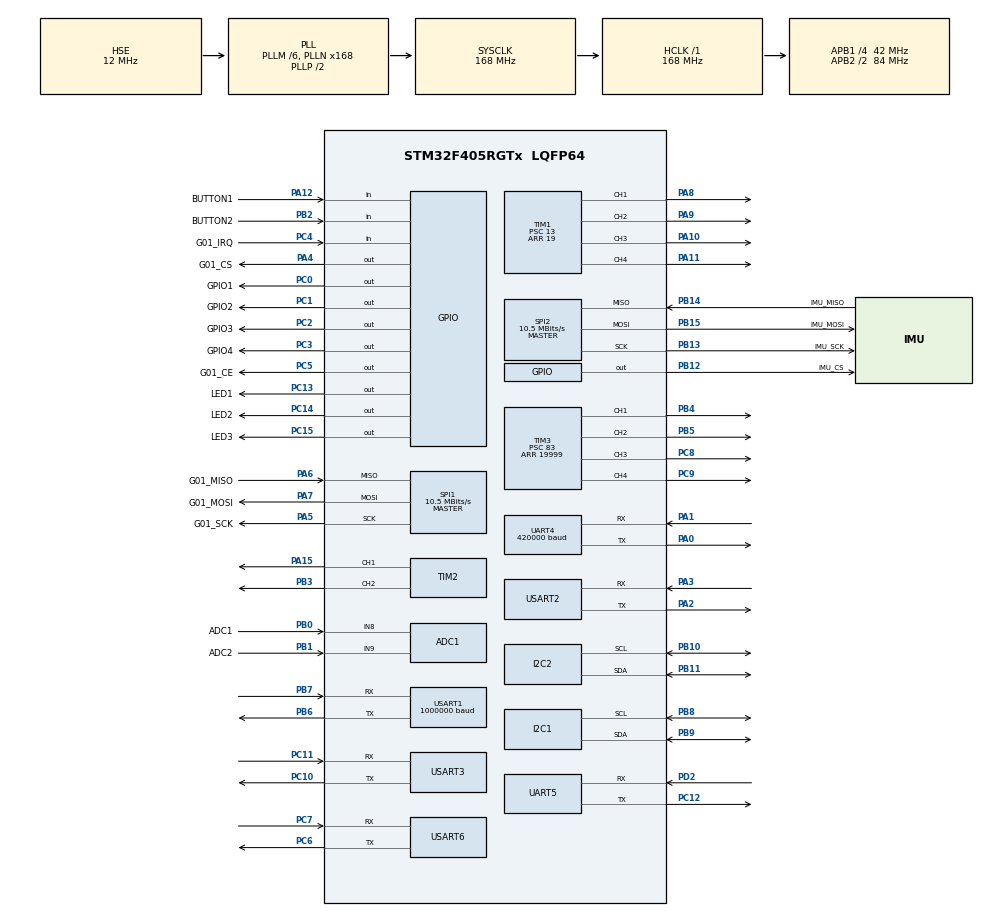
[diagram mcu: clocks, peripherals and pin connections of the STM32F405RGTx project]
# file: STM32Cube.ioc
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ADC1.Channel-0\#ChannelRegularConversion=ADC_CHANNEL_8
ADC1.NbrOfConversionFlag=1
ADC1.Rank-0\#ChannelRegularConversion=1
ADC1.SamplingTime-0\#ChannelRegularConversion=ADC_SAMPLETIME_3CYCLES
ADC1.master=1
Dma.Request0=TIM1_UP
Dma.Request1=USART1_TX
Dma.TIM1_UP.0.Direction=DMA_MEMORY_TO_PERIPH
Dma.TIM1_UP.0.FIFOMode=DMA_FIFOMODE_DISABLE
Dma.TIM1_UP.0.Instance=DMA2_Stream5
Dma.TIM1_UP.0.MemDataAlignment=DMA_MDATAALIGN_WORD
Dma.TIM1_UP.0.MemInc=DMA_MINC_ENABLE
Dma.TIM1_UP.0.Mode=DMA_NORMAL
Dma.TIM1_UP.0.PeriphDataAlignment=DMA_PDATAALIGN_WORD
Dma.TIM1_UP.0.PeriphInc=DMA_PINC_DISABLE
Dma.TIM1_UP.0.Priority=DMA_PRIORITY_HIGH
Dma.USART1_TX.1.Direction=DMA_MEMORY_TO_PERIPH
Dma.USART1_TX.1.FIFOMode=DMA_FIFOMODE_DISABLE
Dma.USART1_TX.1.Instance=DMA2_Stream7
Dma.USART1_TX.1.MemDataAlignment=DMA_MDATAALIGN_BYTE
Dma.USART1_TX.1.MemInc=DMA_MINC_ENABLE
Dma.USART1_TX.1.Mode=DMA_NORMAL
Dma.USART1_TX.1.PeriphDataAlignment=DMA_PDATAALIGN_BYTE
Dma.USART1_TX.1.PeriphInc=DMA_PINC_DISABLE
Dma.USART1_TX.1.Priority=DMA_PRIORITY_LOW
Mcu.Family=STM32F4
Mcu.Name=STM32F405RGTx
Mcu.Package=LQFP64
NVIC.DMA2_Stream5_IRQn=true\:3\:0\:true\:false\:true\:false\:true\:true
NVIC.DMA2_Stream7_IRQn=true\:2\:0\:true\:false\:true\:false\:true\:true
NVIC.PriorityGroup=NVIC_PRIORITYGROUP_4
NVIC.TIM3_IRQn=true\:4\:0\:true\:false\:true\:true\:true\:true
NVIC.TIM6_DAC_IRQn=true\:4\:0\:true\:false\:true\:true\:true\:true
NVIC.UART4_IRQn=true\:1\:0\:true\:false\:true\:true\:true\:true
PA0-WKUP.Mode=Asynchronous
PA0-WKUP.Signal=UART4_TX
PA1.Mode=Asynchronous
PA1.Signal=UART4_RX
PA10.Signal=S_TIM1_CH3
PA11.Signal=S_TIM1_CH4
PA12.GPIO_Label=BUTTON1
PA12.GPIO_PuPd=GPIO_PULLUP
PA12.Signal=GPIO_Input
PA13.Mode=Serial_Wire
PA13.Signal=SYS_JTMS-SWDIO
PA14.Mode=Serial_Wire
PA14.Signal=SYS_JTCK-SWCLK
PA15.Signal=S_TIM2_CH1_ETR
PA2.Mode=Asynchronous
PA2.Signal=USART2_TX
PA3.Mode=Asynchronous
PA3.Signal=USART2_RX
PA4.GPIO_Label=G01_CS
PA4.GPIO_Speed=GPIO_SPEED_FREQ_VERY_HIGH
PA4.PinState=GPIO_PIN_SET
PA4.Signal=GPIO_Output
PA5.GPIO_Label=G01_SCK
PA5.Mode=Full_Duplex_Master
PA5.Signal=SPI1_SCK
PA6.GPIO_Label=G01_MISO
PA6.Mode=Full_Duplex_Master
PA6.Signal=SPI1_MISO
PA7.GPIO_Label=G01_MOSI
PA7.Mode=Full_Duplex_Master
PA7.Signal=SPI1_MOSI
PA8.Signal=S_TIM1_CH1
PA9.Signal=S_TIM1_CH2
PB0.GPIO_Label=ADC1
PB0.Signal=ADCx_IN8
PB1.GPIO_Label=ADC2
PB1.Signal=ADCx_IN9
PB10.Mode=I2C
PB10.Signal=I2C2_SCL
PB11.Mode=I2C
PB11.Signal=I2C2_SDA
PB12.GPIO_Label=IMU_CS
PB12.GPIO_Speed=GPIO_SPEED_FREQ_VERY_HIGH
PB12.PinState=GPIO_PIN_SET
PB12.Signal=GPIO_Output
PB13.GPIO_Label=IMU_SCK
PB13.Mode=Full_Duplex_Master
PB13.Signal=SPI2_SCK
PB14.GPIO_Label=IMU_MISO
PB14.Mode=Full_Duplex_Master
PB14.Signal=SPI2_MISO
PB15.GPIO_Label=IMU_MOSI
PB15.Mode=Full_Duplex_Master
PB15.Signal=SPI2_MOSI
PB2.GPIO_Label=BUTTON2
PB2.GPIO_PuPd=GPIO_PULLUP
PB2.Signal=GPIO_Input
PB3.Signal=S_TIM2_CH2
PB4.Signal=S_TIM3_CH1
PB5.Signal=S_TIM3_CH2
PB6.Mode=Asynchronous
PB6.Signal=USART1_TX
PB7.Mode=Asynchronous
PB7.Signal=USART1_RX
PB8.Mode=I2C
PB8.Signal=I2C1_SCL
PB9.Mode=I2C
PB9.Signal=I2C1_SDA
PC0.GPIO_Label=GPIO1
PC0.GPIO_Speed=GPIO_SPEED_FREQ_VERY_HIGH
PC0.PinState=GPIO_PIN_RESET
PC0.Signal=GPIO_Output
PC1.GPIO_Label=GPIO2
PC1.GPIO_Speed=GPIO_SPEED_FREQ_VERY_HIGH
PC1.Signal=GPIO_Output
PC10.Mode=Asynchronous
PC10.Signal=USART3_TX
PC11.Mode=Asynchronous
PC11.Signal=USART3_RX
PC12.Mode=Asynchronous
PC12.Signal=UART5_TX
PC13-ANTI_TAMP.GPIO_Label=LED1
PC13-ANTI_TAMP.PinState=GPIO_PIN_SET
PC13-ANTI_TAMP.Signal=GPIO_Output
PC14-OSC32_IN.GPIO_Label=LED2
PC14-OSC32_IN.PinState=GPIO_PIN_SET
PC14-OSC32_IN.Signal=GPIO_Output
PC15-OSC32_OUT.GPIO_Label=LED3
PC15-OSC32_OUT.PinState=GPIO_PIN_SET
PC15-OSC32_OUT.Signal=GPIO_Output
PC2.GPIO_Label=GPIO3
PC2.GPIO_Speed=GPIO_SPEED_FREQ_VERY_HIGH
PC2.Signal=GPIO_Output
PC3.GPIO_Label=GPIO4
PC3.GPIO_Speed=GPIO_SPEED_FREQ_VERY_HIGH
PC3.Signal=GPIO_Output
PC4.GPIO_Label=G01_IRQ
PC4.GPIO_PuPd=GPIO_PULLUP
PC4.Signal=GPIO_Input
PC5.GPIO_Label=G01_CE
PC5.GPIO_Speed=GPIO_SPEED_FREQ_VERY_HIGH
PC5.PinState=GPIO_PIN_SET
PC5.Signal=GPIO_Output
PC6.Mode=Asynchronous
PC6.Signal=USART6_TX
PC7.Mode=Asynchronous
PC7.Signal=USART6_RX
PC8.Signal=S_TIM3_CH3
PC9.Signal=S_TIM3_CH4
PD2.Mode=Asynchronous
PD2.Signal=UART5_RX
PH0-OSC_IN.Mode=HSE-External-Oscillator
PH0-OSC_IN.Signal=RCC_OSC_IN
PH1-OSC_OUT.Mode=HSE-External-Oscillator
PH1-OSC_OUT.Signal=RCC_OSC_OUT
ProjectManager.HeapSize=0x200
ProjectManager.StackSize=0x400
ProjectManager.TargetToolchain=MDK-ARM V5.32
RCC.48MHZClocksFreq_Value=84000000
RCC.AHBFreq_Value=168000000
RCC.APB1CLKDivider=RCC_HCLK_DIV4
RCC.APB1Freq_Value=42000000
RCC.APB1TimFreq_Value=84000000
RCC.APB2CLKDivider=RCC_HCLK_DIV2
RCC.APB2Freq_Value=84000000
RCC.APB2TimFreq_Value=168000000
RCC.CortexFreq_Value=168000000
RCC.HCLKFreq_Value=168000000
RCC.HSE_VALUE=12000000
RCC.HSI_VALUE=16000000
RCC.LSE_VALUE=32768
RCC.PLLM=6
RCC.PLLN=168
RCC.PLLSourceVirtual=RCC_PLLSOURCE_HSE
RCC.SYSCLKFreq_VALUE=168000000
RCC.SYSCLKSource=RCC_SYSCLKSOURCE_PLLCLK
RCC.VCOOutputFreq_Value=336000000
SH.ADCx_IN8.0=ADC1_IN8,IN8
SH.ADCx_IN9.0=ADC1_IN9,IN9
SH.S_TIM1_CH1.0=TIM1_CH1,PWM Generation1 CH1
SH.S_TIM1_CH2.0=TIM1_CH2,PWM Generation2 CH2
SH.S_TIM1_CH3.0=TIM1_CH3,PWM Generation3 CH3
SH.S_TIM1_CH4.0=TIM1_CH4,PWM Generation4 CH4
SH.S_TIM2_CH1_ETR.0=TIM2_CH1,PWM Generation1 CH1
SH.S_TIM2_CH2.0=TIM2_CH2,PWM Generation2 CH2
SH.S_TIM3_CH1.0=TIM3_CH1,PWM Generation1 CH1
SH.S_TIM3_CH2.0=TIM3_CH2,PWM Generation2 CH2
SH.S_TIM3_CH3.0=TIM3_CH3,PWM Generation3 CH3
SH.S_TIM3_CH4.0=TIM3_CH4,PWM Generation4 CH4
SPI1.BaudRatePrescaler=SPI_BAUDRATEPRESCALER_8
SPI1.CalculateBaudRate=10.5 MBits/s
SPI1.Direction=SPI_DIRECTION_2LINES
SPI1.Mode=SPI_MODE_MASTER
SPI1.VirtualType=VM_MASTER
SPI2.BaudRatePrescaler=SPI_BAUDRATEPRESCALER_4
SPI2.CLKPhase=SPI_PHASE_2EDGE
SPI2.CLKPolarity=SPI_POLARITY_HIGH
SPI2.CalculateBaudRate=10.5 MBits/s
SPI2.Direction=SPI_DIRECTION_2LINES
SPI2.Mode=SPI_MODE_MASTER
SPI2.VirtualType=VM_MASTER
TIM1.AutoReloadPreload=TIM_AUTORELOAD_PRELOAD_ENABLE
TIM1.Channel-PWM\ Generation1\ CH1=TIM_CHANNEL_1
TIM1.Channel-PWM\ Generation2\ CH2=TIM_CHANNEL_2
TIM1.Channel-PWM\ Generation3\ CH3=TIM_CHANNEL_3
TIM1.Channel-PWM\ Generation4\ CH4=TIM_CHANNEL_4
TIM1.Period=19
TIM1.Prescaler=13
TIM2.Channel-PWM\ Generation1\ CH1=TIM_CHANNEL_1
TIM2.Channel-PWM\ Generation2\ CH2=TIM_CHANNEL_2
TIM3.AutoReloadPreload=TIM_AUTORELOAD_PRELOAD_ENABLE
TIM3.Channel-PWM\ Generation1\ CH1=TIM_CHANNEL_1
TIM3.Channel-PWM\ Generation2\ CH2=TIM_CHANNEL_2
TIM3.Channel-PWM\ Generation3\ CH3=TIM_CHANNEL_3
TIM3.Channel-PWM\ Generation4\ CH4=TIM_CHANNEL_4
TIM3.Period=19999
TIM3.Prescaler=83
TIM6.AutoReloadPreload=TIM_AUTORELOAD_PRELOAD_ENABLE
TIM6.Period=999
TIM6.Prescaler=83
UART4.BaudRate=420000
UART4.VirtualMode=Asynchronous
UART5.VirtualMode=Asynchronous
USART1.BaudRate=1000000
USART1.VirtualMode=VM_ASYNC
USART2.VirtualMode=VM_ASYNC
USART3.VirtualMode=VM_ASYNC
USART6.VirtualMode=VM_ASYNC
VP_TIM1_VS_ClockSourceINT.Mode=Internal
VP_TIM3_VS_ClockSourceINT.Mode=Internal
VP_TIM6_VS_ClockSourceINT.Mode=Enable_Timer
board=custom

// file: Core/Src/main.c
/* USER CODE BEGIN Header */
/**
  ******************************************************************************
  * @file           : main.c
  * @brief          : Main program body
  ******************************************************************************
  * @attention
  *
  * Copyright (c) 2025 STMicroelectronics.
  * All rights reserved.
  *
  * This software is licensed under terms that can be found in the LICENSE file
  * in the root directory of this software component.
  * If no LICENSE file comes with this software, it is provided AS-IS.
  *
  ******************************************************************************
  */
/* USER CODE END Header */
#include "main.h"
#include "adc.h"
#include "dma.h"
#include "i2c.h"
#include "spi.h"
#include "tim.h"
#include "usart.h"
#include "gpio.h"

/* USER CODE BEGIN Includes */
#include "system.h"

/* USER CODE END Includes */

void SystemClock_Config(void);

int main(void)
{

  /* MCU Configuration--------------------------------------------------------*/

  /* Reset of all peripherals, Initializes the Flash interface and the Systick. */
  HAL_Init();

  /* Configure the system clock */
  SystemClock_Config();

  /* Initialize all configured peripherals */
  MX_GPIO_Init();
  MX_DMA_Init();
  MX_ADC1_Init();
  MX_I2C1_Init();
  MX_I2C2_Init();
  MX_SPI1_Init();
  MX_SPI2_Init();
  MX_TIM1_Init();
  MX_TIM2_Init();
  MX_TIM3_Init();
  MX_UART4_Init();
  MX_UART5_Init();
  MX_USART1_UART_Init();
  MX_USART2_UART_Init();
  MX_USART3_UART_Init();
  MX_USART6_UART_Init();
  MX_TIM6_Init();
  /* USER CODE BEGIN 2 */
  system_init();
  /* USER CODE END 2 */

  /* Infinite loop */
  while (1)
  {

    /* USER CODE BEGIN 3 */
    system_loop();
  }
  /* USER CODE END 3 */
}

void SystemClock_Config(void)
{
  RCC_OscInitTypeDef RCC_OscInitStruct = {0};
  RCC_ClkInitTypeDef RCC_ClkInitStruct = {0};

  /** Configure the main internal regulator output voltage
  */
  __HAL_RCC_PWR_CLK_ENABLE();
  __HAL_PWR_VOLTAGESCALING_CONFIG(PWR_REGULATOR_VOLTAGE_SCALE1);

  /** Initializes the RCC Oscillators according to the specified parameters
  * in the RCC_OscInitTypeDef structure.
  */
  RCC_OscInitStruct.OscillatorType = RCC_OSCILLATORTYPE_HSE;
  RCC_OscInitStruct.HSEState = RCC_HSE_ON;
  RCC_OscInitStruct.PLL.PLLState = RCC_PLL_ON;
  RCC_OscInitStruct.PLL.PLLSource = RCC_PLLSOURCE_HSE;
  RCC_OscInitStruct.PLL.PLLM = 6;
  RCC_OscInitStruct.PLL.PLLN = 168;
  RCC_OscInitStruct.PLL.PLLP = RCC_PLLP_DIV2;
  RCC_OscInitStruct.PLL.PLLQ = 4;
  if (HAL_RCC_OscConfig(&RCC_OscInitStruct) != HAL_OK)
  {
    Error_Handler();
  }

  /** Initializes the CPU, AHB and APB buses clocks
  */
  RCC_ClkInitStruct.ClockType = RCC_CLOCKTYPE_HCLK|RCC_CLOCKTYPE_SYSCLK
                              |RCC_CLOCKTYPE_PCLK1|RCC_CLOCKTYPE_PCLK2;
  RCC_ClkInitStruct.SYSCLKSource = RCC_SYSCLKSOURCE_PLLCLK;
  RCC_ClkInitStruct.AHBCLKDivider = RCC_SYSCLK_DIV1;
  RCC_ClkInitStruct.APB1CLKDivider = RCC_HCLK_DIV4;
  RCC_ClkInitStruct.APB2CLKDivider = RCC_HCLK_DIV2;

  if (HAL_RCC_ClockConfig(&RCC_ClkInitStruct, FLASH_LATENCY_5) != HAL_OK)
  {
    Error_Handler();
  }
}

void Error_Handler(void)
{
  __disable_irq();
  while (1)
  {
  }
}
